# SSI register map
Vendor: Texas Instruments
Peripheral module from a debugger description file (folder cc2538).
Registers are 32-bit, access per field, no defined reset value unless marked. A register's access mark holds for its fields unless they carry their own. Offsets are as the file gives them; lines under a group give offsets from that group; [hi:lo] are bit positions; {n}, {i} and the like mark numbered series; 'fields as' and 'values as' point back to an identical list; <NAME> marks a mode.

## SSI — Register fields should be considered static unless otherwise noted as dynamic.
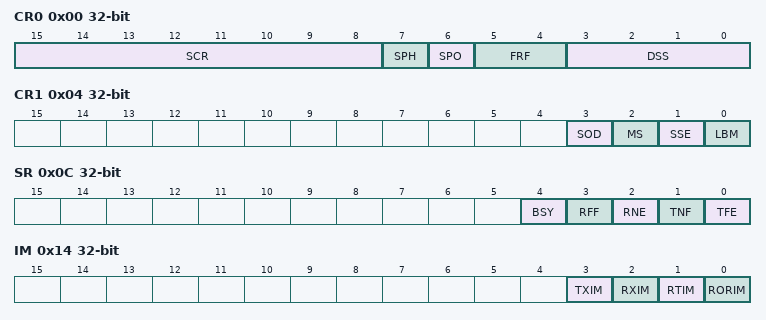
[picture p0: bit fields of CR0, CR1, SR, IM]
0x00 CR0 — The CR0 register contains bit fields that control various functions within the SSI module. Functionality such as protocol mode, clock rate, and data size are configured in this register.
  [15:8] SCR rw — SSI serial clock rate (R/W) Reset value: 0x0 The value SCR is used to generate the transmit and receive bit rate of the SSI. Where the bit rate is: BR = FSSICLK/(CPSDVR * (1 + SCR)) where CPSDVR is an even value from 2-254, programmed in the SSICPSR register and SCR is a value from 0-255.
  [7] SPH rw — SSI serial clock phase (R/W) Reset value: 0x0 This bit is only applicable to the Motorola SPI Format.
  [6] SPO rw — SSI serial clock phase (R/W) Reset value: 0x0 This bit is only applicable to the Motorola SPI Format.
  [5:4] FRF rw — SSI frame format select (R/W) Reset value: 0x0 00: Motorola SPI frame format 01: TI synchronous serial frame format 10: National Microwire frame format 11: Reserved
  [3:0] DSS rw — SSI data size select (R/W) Reset value: 0x0 0000-0010: Reserved 0011: 4-bit data 0100: 5-bit data 0101: 6-bit data 0110: 7-bit data 0111: 8-bit data 1000: 9-bit data 1001: 10-bit data 1010: 11-bit data 1011: 12-bit data 1100: 13-bit data 1101: 14-bit data 1110: 15-bit data 1111: 16-bit data
0x04 CR1 rw — The CR1 register contains bit fields that control various functions within the SSI module. Master and slave mode functionality is controlled by this register.
  [3] SOD — SSI slave mode output disable (R/W) Reset value: 0x0 This bit is relevant only in the slave mode (MS = 1). In multiple-slave systems, it is possible for the SSI master to broadcast a message to all slaves in the system while ensuring that only one slave drives data onto the serial output line. In such systems, the RXD lines from multiple slaves could be tied together. To operate in such a system, the SOD bit can be set if the SSI slave is not suppose to drive the SSITXD line. 0: SSI can drive SSITXD in slave output mode 1: SSI must not drive the SSITXD output in slave mode
  [2] MS — SSI master and slave select (R/W) Reset value: 0x0 This bit can be modified only when the SSI is disabled (SSE = 0). 0: Device configured as a master (default) 1: Device configured as a slave
  [1] SSE — SSI synchronous serial port enable (R/W) Reset value: 0x0 0: SSI operation is disabled. 1: SSI operation is enabled.
  [0] LBM — SSI loop-back mode (R/W) Reset value: 0x0 0: Normal serial port operation is enabled. 1: The output of the transmit serial shifter is connected to the input of the receive serial shift register internally.
0x08 DR — The DR register is 16 bits wide. When the SSIDR register is read, the entry in the receive FIFO that is pointed to by the current FIFO read pointer is accessed. When a data value is removed by the SSI receive logic from the incoming data frame, it is placed into the entry in the receive FIFO pointed to by the current FIFO write pointer. When the DR register is written to, the entry in the transmit FIFO that is pointed to by the write pointer is written to. Data values are removed from the transmit FIFO one value at a time by the transmit logic. Each data value is loaded into the transmit serial shifter, then serially shifted out onto the SSITx pin at the programmed bit rate. When a data size of less than 16 bits is selected, the user must right-justify data written to the transmit FIFO. The transmit logic ignores the unused bits. Received data less than 16 bits is automatically right-justified in the receive buffer. When the SSI is programmed for MICROWIRE frame format, the default size for transmit data is eight bits (the most significant byte is ignored). The receive data size is controlled by the programmer. The transmit FIFO and the receive FIFO are not cleared even when the SSE bit in the SSICR1 register is cleared, allowing the software to fill the transmit FIFO before enabling the SSI.
  [15:0] DATA rw — SSI receive/transmit data register (R/W) Reset value: 0xXXXX A read operation reads the receive FIFO. A write operation writes the transmit FIFO. Software must right-justify data when the SSI is programmed for a data size that is less than 16 bits. Unused bits at the top are ignored by the transmit logic. The receive logic automatically right-justified the data.
0x0C SR ro — The SR register contains bits that indicate the FIFO fill status and the SSI busy status.
  [4] BSY — SSI busy bit (RO) Reset value: 0x0 0: SSI is idle. 1: SSI is currently transmitting and/or receiving a frame or the transmit FIFO is not empty.
  [3] RFF — SSI receive FIFO full (RO) Reset value: 0x0 0: Receive FIFO is not full. 1: Receive FIFO is full.
  [2] RNE — SSI receive FIFO not empty (RO) Reset value: 0x0 0: Receive FIFO is empty. 1: Receive FIFO is not empty.
  [1] TNF — SSI transmit FIFO not full (RO) Reset value: 0x1 0: Transmit FIFO is full. 1: Transmit FIFO is not full.
  [0] TFE — SSI transmit FIFO empty (RO) Reset value: 0x1 0: Transmit FIFO is not empty. 1: Transmit FIFO is empty.
0x10 CPSR — The CPSR register specifies the division factor which is used to derive the SSIClk from the system clock. The clock is further divided by a value from 1 to 256, which is 1 + SCR. SCR is programmed in the SSICR0 register. The frequency of the SSIClk is defined by: SSIClk = SysClk / (CPSDVSR x (1 + SCR)) The value programmed into this register must be an even number between 2 and 254. The least-significant bit of the programmed number is hard-coded to zero. If an odd number is written to this register, data read back from this register has the least-significant bit as zero.
  [7:0] CPSDVSR rw — SSI clock prescale divisor (R/W) Reset value: 0x0 This value must be an even number from 2 to 254, depending on the frequency of SSICLK. The LSB always returns zero on reads.
0x14 IM — The IM register is the interrupt mask set or clear register. It is a read/write register and all bits are cleared on reset. On a read, this register gives the current value of the mask on the corresponding interrupt. Setting a bit sets the mask, preventing the interrupt from being signaled to the interrupt controller. Clearing a bit clears the corresponding mask, enabling the interrupt to be sent to the interrupt controller.
  [3] TXIM rw — SSI transmit FIFO interrupt mask (R/W) Reset value: 0x0 0: TX FIFO half empty or condition interrupt is masked. 1: TX FIFO half empty or less condition interrupt is not masked.
  [2] RXIM rw — SSI receive FIFO interrupt mask (R/W) Reset value: 0x0 0: RX FIFO half empty or condition interrupt is masked. 1: RX FIFO half empty or less condition interrupt is not masked.
  [1] RTIM rw — SSI receive time-out interrupt mask (R/W) Reset value: 0x0 0: RX FIFO time-out interrupt is masked. 1: RX FIFO time-out interrupt is not masked
  [0] RORIM rw — SSI receive overrun interrupt mask (R/W) Reset value: 0x0 0: RX FIFO Overrun interrupt is masked. 1: RX FIFO Overrun interrupt is not masked
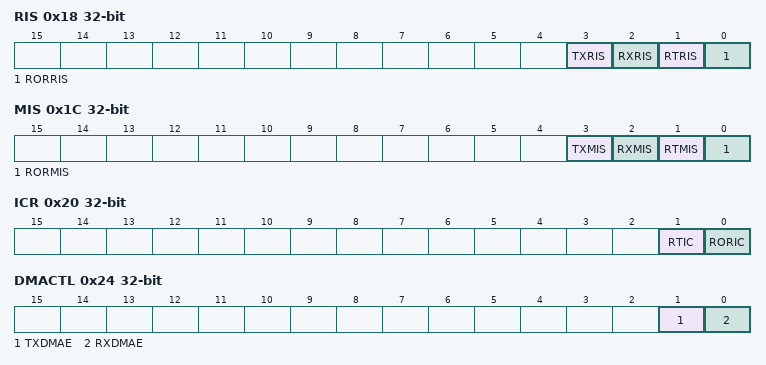
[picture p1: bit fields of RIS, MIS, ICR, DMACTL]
0x18 RIS ro — The RIS register is the raw interrupt status register. On a read, this register gives the current raw status value of the corresponding interrupt before masking. A write has no effect.
  [3] TXRIS — SSI SSITXINTR raw state (RO) Reset value: 0x1 Gives the raw interrupt state (before masking) of SSITXINTR
  [2] RXRIS — SSI SSIRXINTR raw state (RO) Reset value: 0x0 Gives the raw interrupt state (before masking) of SSIRXINTR
  [1] RTRIS — SSI SSIRTINTR raw state (RO) Reset value: 0x0 Gives the raw interrupt state (before masking) of SSIRTINTR
  [0] RORRIS — SSI SSIRORINTR raw state (RO) Reset value: 0x0 Gives the raw interrupt state (before masking) of SSIRORINTR
0x1C MIS ro — The MIS register is the masked interrupt status register. On a read, this register gives the current masked status value of the corresponding interrupt. A write has no effect.
  [3] TXMIS — SSI SSITXINTR masked state (RO) Reset value: 0x0 Gives the interrupt state (after masking) of SSITXINTR
  [2] RXMIS — SSI SSIRXINTR masked state (RO) Reset value: 0x0 Gives the interrupt state (after masking) of SSIRXINTR
  [1] RTMIS — SSI SSIRTINTR masked state (RO) Reset value: 0x0 Gives the interrupt state (after masking) of SSIRTINTR
  [0] RORMIS — SSI SSIRORINTR masked state (RO) Reset value: 0x0 Gives the interrupt state (after masking) of SSIRORINTR
0x20 ICR — The ICR register is the interrupt clear register. On a write of 1, the corresponding interrupt is cleared. A write of 0 has no effect.
  [1] RTIC rw — SSI receive time-out interrupt clear (W1C) Reset value: 0x0 0: No effect on interrupt 1: Clears interrupt
  [0] RORIC rw — SSI receive overrun interrupt clear (W1C) Reset value: 0x0 0: No effect on interrupt 1: Clears interrupt
0x24 DMACTL — The DMACTL register is the uDMA control register.
  [1] TXDMAE rw — Transmit DMA enable 0: uDMA for the transmit FIFO is disabled. 1: uDMA for the transmit FIFO is enabled.
  [0] RXDMAE rw — Receive DMA enable 0: uDMA for the receive FIFO is disabled. 1: uDMA for the receive FIFO is enabled.
0xFC8 CC — SSI clock configuration The CC register controls the baud clock and system clocks sources for the SSI module. Note: If the PIOSC is used for the SSI baud clock, the system clock frequency must be at least 16 MHz in run mode.
  [2:0] CS rw — SSI baud and system clock source The following bits determine the clock source that generates the baud and system clocks for the SSI. bit0 (PIOSC): 1: The SSI baud clock is determined by the IO DIV setting in the system controller. 0: The SSI baud clock is determined by the SYS DIV setting in the system controller. bit1: Unused bit2: (DSEN) Only meaningful when the system is in deep sleep mode. This bit is a don't care when not in sleep mode. 1: The SSI system clock is running on the same clock as the baud clock, as per PIOSC setting above. 0: The SSI system clock is determined by the SYS DIV setting in the system controller.
